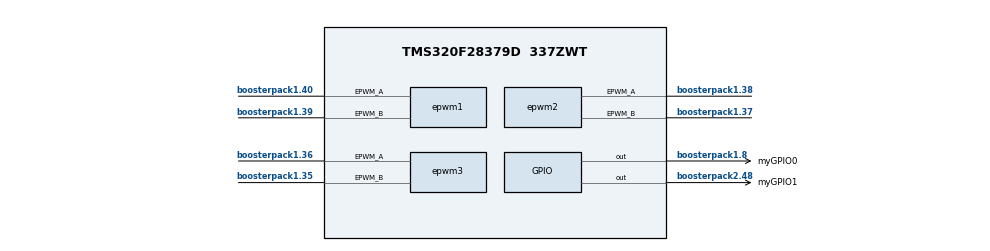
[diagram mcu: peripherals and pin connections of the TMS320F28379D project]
/**
 * These arguments were used when this file was generated. They will be automatically applied on subsequent loads
 * via the GUI or CLI. Run CLI with '--help' for additional information on how to override these arguments.
 * @cliArgs --board "/boards/LAUNCHXL_F28379D" --device "F2837xD" --part "F2837xD_337ZWT" --package "F2837xD_337ZWT" --context "CPU1" --product "C2000WARE@5.04.00.00"
 * @v2CliArgs --device "TMS320F28379D" --package "337ZWT" --board "/boards/LAUNCHXL_F28379D" --context "CPU1" --product "C2000WARE@5.04.00.00"
 * @versions {"tool":"1.21.0+3721"}
 */

/**
 * Import the modules used in this configuration.
 */
const adc              = scripting.addModule("/driverlib/adc.js", {}, false);
const adc1             = adc.addInstance();
const adc2             = adc.addInstance();
const cmpss            = scripting.addModule("/driverlib/cmpss.js", {}, false);
const cmpss1           = cmpss.addInstance();
const cputimer         = scripting.addModule("/driverlib/cputimer.js", {}, false);
const cputimer1        = cputimer.addInstance();
const dac              = scripting.addModule("/driverlib/dac.js", {}, false);
const dac1             = dac.addInstance();
const dac2             = dac.addInstance();
const epwm             = scripting.addModule("/driverlib/epwm.js", {}, false);
const epwm1            = epwm.addInstance();
const epwm2            = epwm.addInstance();
const epwm3            = epwm.addInstance();
const epwmxbar         = scripting.addModule("/driverlib/epwmxbar.js", {}, false);
const epwmxbar1        = epwmxbar.addInstance();
const gpio             = scripting.addModule("/driverlib/gpio.js", {}, false);
const gpio1            = gpio.addInstance();
const gpio2            = gpio.addInstance();
const inputxbar_input  = scripting.addModule("/driverlib/inputxbar_input.js", {}, false);
const inputxbar_input1 = inputxbar_input.addInstance();
const inputxbar_input2 = inputxbar_input.addInstance();

/**
 * Write custom configuration values to the imported modules.
 */
adc1.$name                          = "ADC0";
adc1.adcClockPrescaler              = "ADC_CLK_DIV_4_0";
adc1.interruptPulseMode             = "ADC_PULSE_END_OF_CONV";
adc1.enabledInts                    = ["ADC_INT_NUMBER1"];
adc1.enableInterrupt1               = true;
adc1.registerInterrupts             = ["1"];
adc1.soc0SampleWindow               = 16;
adc1.enableInterrupt1ContinuousMode = true;
adc1.soc0Channel                    = "ADC_CH_ADCIN2";
adc1.soc0Trigger                    = "ADC_TRIGGER_CPU1_TINT0";
adc1.enabledSOCs                    = ["ADC_SOC_NUMBER0"];
adc1.adcInt1.enableInterrupt        = true;

adc2.$name                          = "ADC1";
adc2.adcClockPrescaler              = "ADC_CLK_DIV_4_0";
adc2.soc0SampleWindow               = 16;
adc2.enabledInts                    = ["ADC_INT_NUMBER1"];
adc2.enableInterrupt1               = true;
adc2.enableInterrupt1ContinuousMode = true;
adc2.adcBase                        = "ADCC_BASE";
adc2.soc0Channel                    = "ADC_CH_ADCIN2";
adc2.registerInterrupts             = ["1"];
adc2.soc0Trigger                    = "ADC_TRIGGER_CPU1_TINT0";
adc2.enabledSOCs                    = ["ADC_SOC_NUMBER1"];
adc2.soc1Channel                    = "ADC_CH_ADCIN2";
adc2.soc1Trigger                    = "ADC_TRIGGER_CPU1_TINT0";
adc2.soc1SampleWindow               = 16;
adc2.interrupt1SOCSource            = "ADC_SOC_NUMBER1";
adc2.useInterrupts                  = false;

cmpss1.$name        = "myCMPSS0";
cmpss1.enableModule = true;
cmpss1.dacValHigh   = 2048;
cmpss1.cmpssBase    = "CMPSS6_BASE";

cputimer1.$name                    = "myCPUTIMER0";
cputimer1.startTimer               = true;
cputimer1.enableInterrupt          = true;
cputimer1.emulationMode            = "CPUTIMER_EMULATIONMODE_RUNFREE";
cputimer1.registerInterrupts       = true;
cputimer1.timerPeriod              = 4999;
cputimer1.timerInt.enableInterrupt = true;

dac1.$name            = "DAC0";
dac1.enableOutput     = true;
dac1.dacBase          = "DACB_BASE";
dac1.referenceVoltage = "DAC_REF_ADC_VREFHI";

dac2.referenceVoltage = "DAC_REF_ADC_VREFHI";
dac2.enableOutput     = true;
dac2.$name            = "DAC1";

epwm1.epwmTimebase_hsClockDiv                           = "EPWM_HSCLOCK_DIVIDER_1";
epwm1.epwmEventTrigger_EPWM_SOC_A_triggerEnable         = true;
epwm1.epwmEventTrigger_EPWM_SOC_A_triggerSource         = "EPWM_SOC_TBCTR_ZERO_OR_PERIOD";
epwm1.epwmEventTrigger_EPWM_SOC_A_triggerEventPrescalar = "1";
epwm1.$name                                             = "myEPWM1";
epwm1.epwmDeadband_enableFED                            = true;
epwm1.epwmDeadband_delayRED                             = 50;
epwm1.epwmDeadband_delayFED                             = 50;
epwm1.epwmDeadband_polarityFED                          = "EPWM_DB_POLARITY_ACTIVE_LOW";
epwm1.epwmDeadband_enableRED                            = true;
epwm1.epwm.$assign                                      = "EPWM1";
epwm1.epwm.epwm_aPin.$assign                            = "boosterpack1.40";
epwm1.epwm.epwm_bPin.$assign                            = "boosterpack1.39";

epwm2.$name                                             = "myEPWM2";
epwm2.epwmTimebase_hsClockDiv                           = "EPWM_HSCLOCK_DIVIDER_1";
epwm2.epwmDeadband_polarityFED                          = "EPWM_DB_POLARITY_ACTIVE_LOW";
epwm2.epwmDeadband_enableRED                            = true;
epwm2.epwmDeadband_enableFED                            = true;
epwm2.epwmDeadband_redShadowMode                        = true;
epwm2.epwmDeadband_delayRED                             = 50;
epwm2.epwmDeadband_fedShadowMode                        = true;
epwm2.epwmDeadband_delayFED                             = 50;
epwm2.epwmEventTrigger_EPWM_SOC_A_triggerEnable         = true;
epwm2.epwmEventTrigger_EPWM_SOC_A_triggerSource         = "EPWM_SOC_TBCTR_ZERO_OR_PERIOD";
epwm2.epwmEventTrigger_EPWM_SOC_A_triggerEventPrescalar = "1";
epwm2.epwm.$assign                                      = "EPWM2";
epwm2.epwm.epwm_aPin.$assign                            = "boosterpack1.38";
epwm2.epwm.epwm_bPin.$assign                            = "boosterpack1.37";

epwm3.$name                                             = "myEPWM3";
epwm3.epwmTimebase_hsClockDiv                           = "EPWM_HSCLOCK_DIVIDER_1";
epwm3.epwmDeadband_polarityFED                          = "EPWM_DB_POLARITY_ACTIVE_LOW";
epwm3.epwmDeadband_enableRED                            = true;
epwm3.epwmDeadband_enableFED                            = true;
epwm3.epwmDeadband_redShadowMode                        = true;
epwm3.epwmDeadband_delayRED                             = 50;
epwm3.epwmDeadband_fedShadowMode                        = true;
epwm3.epwmDeadband_delayFED                             = 50;
epwm3.epwmEventTrigger_EPWM_SOC_A_triggerEnable         = true;
epwm3.epwmEventTrigger_EPWM_SOC_A_triggerSource         = "EPWM_SOC_TBCTR_ZERO_OR_PERIOD";
epwm3.epwmEventTrigger_EPWM_SOC_A_triggerEventPrescalar = "1";
epwm3.epwm.$assign                                      = "EPWM3";
epwm3.epwm.epwm_aPin.$assign                            = "boosterpack1.36";
epwm3.epwm.epwm_bPin.$assign                            = "boosterpack1.35";

epwmxbar1.$name     = "myEPWMXBAR0";
epwmxbar1.muxesUsed = ["XBAR_MUX10"];

gpio1.$name                     = "myGPIO0";
gpio1.useInterrupt              = true;
gpio1.gpioPin.$assign           = "boosterpack1.8";
gpio1.xint.intType              = "GPIO_INT_TYPE_BOTH_EDGES";
gpio1.xint.registerInterrupts   = true;
gpio1.xint.enableInt            = true;
gpio1.xint.xInt.enableInterrupt = true;

gpio2.$name           = "myGPIO1";
gpio2.gpioPin.$assign = "boosterpack2.48";

inputxbar_input1.$name         = "myINPUTXBARINPUT0";
gpio1.xint.inputxbar           = inputxbar_input1;
inputxbar_input1.inputxbarGpio = "GPIO22";

inputxbar_input2.$name         = "myINPUTXBARINPUT1";
inputxbar_input2.inputxbarGpio = "GPIO52";
